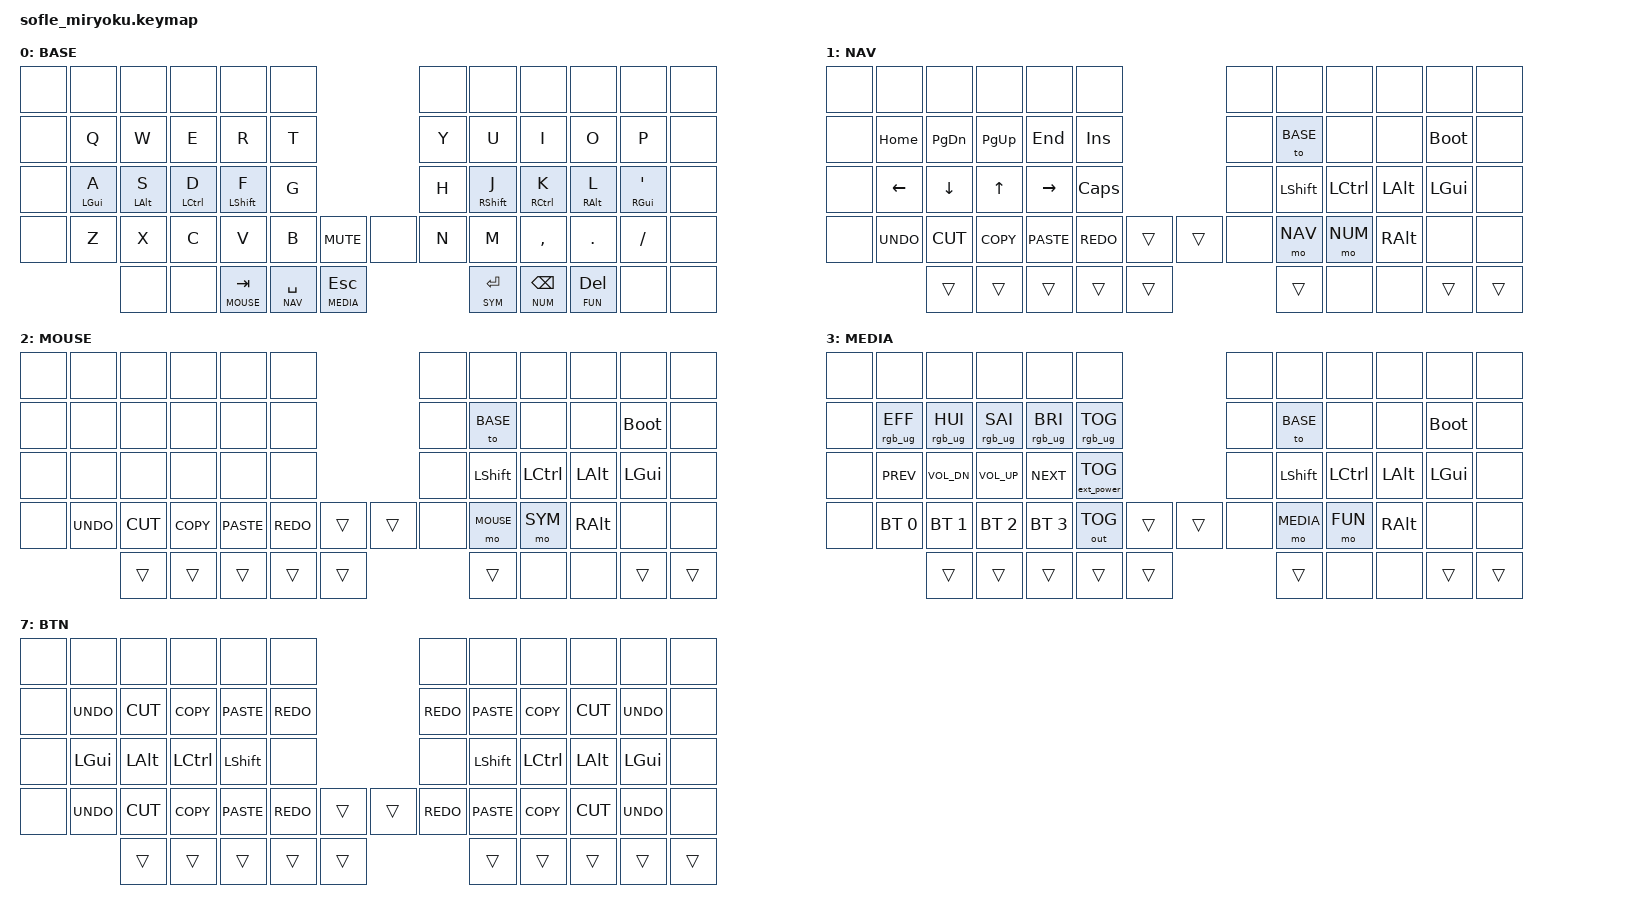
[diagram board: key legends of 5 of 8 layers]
/*
 * Miryoku-inspired keymap for Sofle keyboard
 * Based on Miryoku ZMK layout with flipped layers option
 * Copyright (c) 2020 The ZMK Contributors
 * SPDX-License-Identifier: MIT
 */

#include <behaviors.dtsi>
#include <dt-bindings/zmk/keys.h>
#include <dt-bindings/zmk/bt.h>
#include <dt-bindings/zmk/rgb.h>
#include <dt-bindings/zmk/outputs.h>
#include <dt-bindings/zmk/ext_power.h>

// Layer definitions
#define BASE 0
#define NAV 1
#define MOUSE 2
#define MEDIA 3
#define NUM 4
#define SYM 5
#define FUN 6
#define BUTTON 7

// Miryoku timing configuration
#define MIRYOKU_TAPPING_TERM 200
#define MIRYOKU_QUICK_TAP 175
#define MIRYOKU_PRIOR_IDLE 150

/ {
    behaviors {
        // Home row mods for left hand (GUI, ALT, CTRL, SHIFT)
        hml: homerow_mods_left {
            compatible = "zmk,behavior-hold-tap";
            #binding-cells = <2>;
            flavor = "balanced";
            tapping-term-ms = <MIRYOKU_TAPPING_TERM>;
            quick-tap-ms = <MIRYOKU_QUICK_TAP>;
            require-prior-idle-ms = <MIRYOKU_PRIOR_IDLE>;
            bindings = <&kp>, <&kp>;
            hold-trigger-on-release;
        };

        // Home row mods for right hand (SHIFT, CTRL, ALT, GUI)
        hmr: homerow_mods_right {
            compatible = "zmk,behavior-hold-tap";
            #binding-cells = <2>;
            flavor = "balanced";
            tapping-term-ms = <MIRYOKU_TAPPING_TERM>;
            quick-tap-ms = <MIRYOKU_QUICK_TAP>;
            require-prior-idle-ms = <MIRYOKU_PRIOR_IDLE>;
            bindings = <&kp>, <&kp>;
            hold-trigger-on-release;
        };

        // Layer-tap behavior for thumb keys
        lt_spc: layer_tap_space {
            compatible = "zmk,behavior-hold-tap";
            #binding-cells = <2>;
            flavor = "balanced";
            tapping-term-ms = <MIRYOKU_TAPPING_TERM>;
            quick-tap-ms = <MIRYOKU_QUICK_TAP>;
            bindings = <&mo>, <&kp>;
        };
    };

    keymap {
        compatible = "zmk,keymap";

        // BASE LAYER - QWERTY with home row mods (Miryoku style)
        // Flipped version: left thumb has Mouse/Nav/Media, right thumb has Sym/Num/Fun
        base_layer {
            display-name = "BASE";
            bindings = <
&none       &none      &none      &none      &none        &none                            &none        &none        &none        &none        &none        &none
&none       &kp Q      &kp W      &kp E      &kp R        &kp T                            &kp Y        &kp U        &kp I        &kp O        &kp P        &none
&none       &hml LGUI A &hml LALT S &hml LCTRL D &hml LSHFT F &kp G                       &kp H        &hmr RSHFT J &hmr RCTRL K &hmr RALT L  &hmr RGUI SQT &none
&none       &kp Z      &kp X      &kp C      &kp V        &kp B        &kp C_MUTE  &none   &kp N        &kp M        &kp COMMA    &kp DOT      &kp SLASH    &none
                       &none      &none      &lt_spc MOUSE TAB &lt_spc NAV SPACE &lt_spc MEDIA ESC  &lt_spc SYM RET &lt_spc NUM BSPC &lt_spc FUN DEL &none &none
            >;

            sensor-bindings =
                <&inc_dec_kp C_VOL_UP C_VOL_DN>,
                <&inc_dec_kp K_SCROLL_UP K_SCROLL_DOWN>;
        };

        // NAV LAYER - Navigation keys (Miryoku flipped: left hand navigation)
        nav_layer {
            display-name = "NAV";
            bindings = <
&none  &none     &none      &none      &none         &none                         &none  &none     &none     &none     &none        &none
&none  &kp HOME  &kp PG_DN  &kp PG_UP  &kp END       &kp INS                       &none  &to BASE  &none     &none     &bootloader  &none
&none  &kp LEFT  &kp DOWN   &kp UP     &kp RIGHT     &kp CAPS                      &none  &kp LSHFT &kp LCTRL &kp LALT  &kp LGUI     &none
&none  &kp K_UNDO &kp K_CUT &kp K_COPY &kp K_PASTE  &kp K_REDO  &trans    &trans  &none  &mo NAV   &mo NUM   &kp RALT  &none        &none
                  &trans    &trans     &trans        &trans      &trans    &trans  &none  &none     &trans    &trans
            >;

            sensor-bindings =
                <&inc_dec_kp C_VOL_UP C_VOL_DN>,
                <&inc_dec_kp PG_UP PG_DN>;
        };

        // MOUSE LAYER - Mouse keys (Miryoku flipped: left hand mouse)
        mouse_layer {
            display-name = "MOUSE";
            bindings = <
&none  &none     &none      &none      &none         &none                         &none  &none     &none     &none     &none        &none
&none  &none     &none      &none      &none         &none                         &none  &to BASE  &none     &none     &bootloader  &none
&none  &none     &none      &none      &none         &none                         &none  &kp LSHFT &kp LCTRL &kp LALT  &kp LGUI     &none
&none  &kp K_UNDO &kp K_CUT &kp K_COPY &kp K_PASTE  &kp K_REDO  &trans    &trans  &none  &mo MOUSE &mo SYM   &kp RALT  &none        &none
                  &trans    &trans     &trans        &trans      &trans    &trans  &none  &none     &trans    &trans
            >;

            sensor-bindings =
                <&inc_dec_kp C_VOL_UP C_VOL_DN>,
                <&inc_dec_kp PG_UP PG_DN>;
        };

        // MEDIA LAYER - Media controls and system (Miryoku flipped: left hand media)
        media_layer {
            display-name = "MEDIA";
            bindings = <
&none  &none        &none        &none        &none        &none                                &none         &none     &none     &none     &none        &none
&none  &rgb_ug RGB_EFF &rgb_ug RGB_HUI &rgb_ug RGB_SAI &rgb_ug RGB_BRI &rgb_ug RGB_TOG      &none         &to BASE  &none     &none     &bootloader  &none
&none  &kp C_PREV   &kp C_VOL_DN &kp C_VOL_UP &kp C_NEXT   &ext_power EP_TOG                &none         &kp LSHFT &kp LCTRL &kp LALT  &kp LGUI     &none
&none  &bt BT_SEL 0 &bt BT_SEL 1 &bt BT_SEL 2 &bt BT_SEL 3 &out OUT_TOG &trans      &trans  &none         &mo MEDIA &mo FUN   &kp RALT  &none        &none
                    &trans       &trans       &trans        &trans       &trans      &trans  &none         &none     &trans    &trans
            >;

            sensor-bindings =
                <&inc_dec_kp C_VOL_UP C_VOL_DN>,
                <&inc_dec_kp C_NEXT C_PREV>;
        };

        // NUM LAYER - Number pad (Miryoku flipped: right hand numbers)
        num_layer {
            display-name = "NUM";
            bindings = <
&none  &none        &none     &none     &none     &none                         &none     &none   &none   &none   &none      &none
&none  &bootloader  &none     &none     &to BASE  &none                         &kp LBKT  &kp N7  &kp N8  &kp N9  &kp RBKT   &none
&none  &kp LGUI     &kp LALT  &kp LCTRL &kp LSHFT &none                         &kp EQUAL &kp N4  &kp N5  &kp N6  &kp SEMI   &none
&none  &none        &kp RALT  &mo NUM   &mo NAV   &none  &trans        &trans   &kp BSLH  &kp N1  &kp N2  &kp N3  &kp GRAVE  &none
                    &trans    &trans    &none     &none  &none         &trans   &kp MINUS &kp N0  &kp DOT
            >;

            sensor-bindings =
                <&inc_dec_kp C_VOL_UP C_VOL_DN>,
                <&inc_dec_kp PG_UP PG_DN>;
        };

        // SYM LAYER - Symbols (Miryoku flipped: right hand symbols)
        sym_layer {
            display-name = "SYM";
            bindings = <
&none  &none        &none     &none      &none     &none                         &none     &none     &none     &none    &none        &none
&none  &bootloader  &none     &none      &to BASE  &none                         &kp LBRC  &kp AMPS  &kp ASTRK &kp LPAR &kp RBRC     &none
&none  &kp LGUI     &kp LALT  &kp LCTRL  &kp LSHFT &none                         &kp PLUS  &kp DLLR  &kp PRCNT &kp CARET &kp COLON   &none
&none  &none        &kp RALT  &mo SYM    &mo MOUSE &none  &trans        &trans   &kp PIPE  &kp EXCL  &kp AT    &kp HASH &kp TILDE    &none
                    &trans    &trans     &none     &none  &none         &trans   &kp UNDER &kp LPAR  &kp RPAR
            >;

            sensor-bindings =
                <&inc_dec_kp C_VOL_UP C_VOL_DN>,
                <&inc_dec_kp PG_UP PG_DN>;
        };

        // FUN LAYER - Function keys (Miryoku flipped: right hand function keys)
        fun_layer {
            display-name = "FUN";
            bindings = <
&none  &none        &none     &none      &none     &none                         &none          &none   &none   &none   &none    &none
&none  &bootloader  &none     &none      &to BASE  &none                         &kp PSCRN      &kp F7  &kp F8  &kp F9  &kp F12  &none
&none  &kp LGUI     &kp LALT  &kp LCTRL  &kp LSHFT &none                         &kp SLCK       &kp F4  &kp F5  &kp F6  &kp F11  &none
&none  &none        &kp RALT  &mo FUN    &mo MEDIA &none  &trans        &trans   &kp PAUSE_BREAK &kp F1  &kp F2  &kp F3  &kp F10  &none
                    &trans    &trans     &none     &none  &none         &trans   &kp TAB        &kp SPACE &kp K_APP
            >;

            sensor-bindings =
                <&inc_dec_kp C_VOL_UP C_VOL_DN>,
                <&inc_dec_kp PG_UP PG_DN>;
        };

        // BUTTON LAYER - Additional button layer (Miryoku)
        button_layer {
            display-name = "BTN";
            bindings = <
&none  &none        &none     &none      &none     &none                         &none     &none     &none      &none     &none        &none
&none  &kp K_UNDO   &kp K_CUT &kp K_COPY &kp K_PASTE &kp K_REDO                 &kp K_REDO &kp K_PASTE &kp K_COPY &kp K_CUT &kp K_UNDO  &none
&none  &kp LGUI     &kp LALT  &kp LCTRL  &kp LSHFT &none                         &none     &kp LSHFT &kp LCTRL  &kp LALT  &kp LGUI     &none
&none  &kp K_UNDO   &kp K_CUT &kp K_COPY &kp K_PASTE &kp K_REDO &trans  &trans  &kp K_REDO &kp K_PASTE &kp K_COPY &kp K_CUT &kp K_UNDO  &none
                    &trans    &trans     &trans     &trans      &trans  &trans   &trans    &trans    &trans     &trans
            >;

            sensor-bindings =
                <&inc_dec_kp C_VOL_UP C_VOL_DN>,
                <&inc_dec_kp PG_UP PG_DN>;
        };
    };
};
